# PIC32MZ2048EFM124 register map
Vendor: Microchip
Registers are 32-bit, read-write, reset 0x0 unless marked. A register's access mark holds for its fields unless they carry their own. Addresses are absolute, and some are shared; only a register's first bit layout is shown; [hi:lo] are bit positions; {n}, {i} and the like mark numbered series.

## PORTH
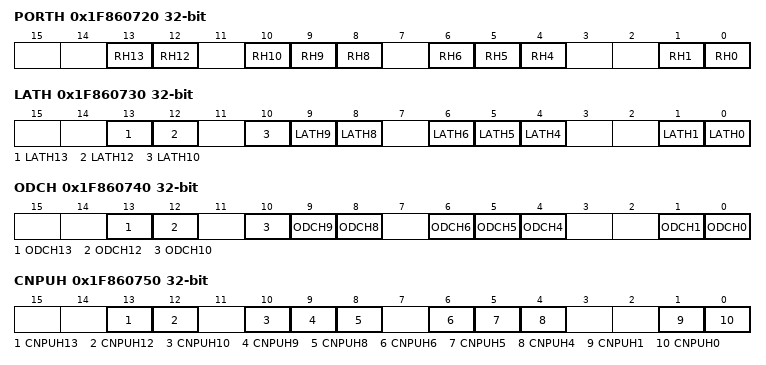
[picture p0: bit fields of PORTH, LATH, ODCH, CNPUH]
0x1F860720 PORTH reset not defined — (power-on value ------------------xx-xxx-xxx--xx)
  [13] RH13, [12] RH12, [10] RH10, [9] RH9, [8] RH8, [6] RH6, [5] RH5, [4] RH4, [1] RH1, [0] RH0
0x1F860730 LATH reset not defined — (power-on value ------------------xx-xxx-xxx--xx)
  [13] LATH13, [12] LATH12, [10] LATH10, [9] LATH9, [8] LATH8, [6] LATH6, [5] LATH5, [4] LATH4, [1] LATH1, [0] LATH0
0x1F860740 ODCH
  [13] ODCH13, [12] ODCH12, [10] ODCH10, [9] ODCH9, [8] ODCH8, [6] ODCH6, [5] ODCH5, [4] ODCH4, [1] ODCH1, [0] ODCH0
0x1F860750 CNPUH
  [13] CNPUH13, [12] CNPUH12, [10] CNPUH10, [9] CNPUH9, [8] CNPUH8, [6] CNPUH6, [5] CNPUH5, [4] CNPUH4, [1] CNPUH1, [0] CNPUH0
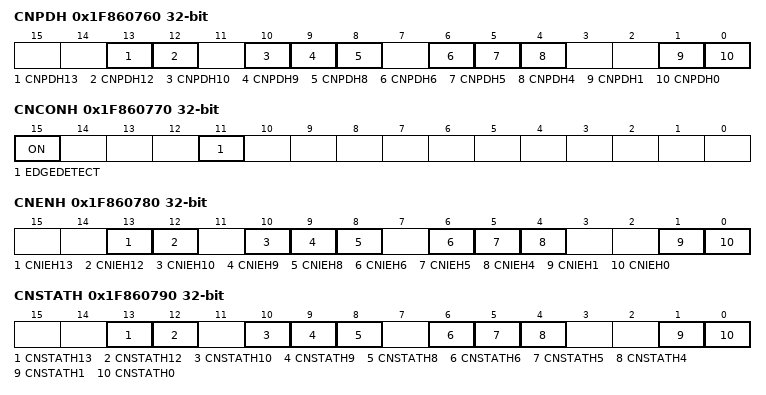
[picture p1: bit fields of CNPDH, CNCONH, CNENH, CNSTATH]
0x1F860760 CNPDH
  [13] CNPDH13, [12] CNPDH12, [10] CNPDH10, [9] CNPDH9, [8] CNPDH8, [6] CNPDH6, [5] CNPDH5, [4] CNPDH4, [1] CNPDH1, [0] CNPDH0
0x1F860770 CNCONH
  [15] ON, [11] EDGEDETECT
0x1F860780 CNENH
  [13] CNIEH13, [12] CNIEH12, [10] CNIEH10, [9] CNIEH9, [8] CNIEH8, [6] CNIEH6, [5] CNIEH5, [4] CNIEH4, [1] CNIEH1, [0] CNIEH0
0x1F860790 CNSTATH
  [13] CNSTATH13, [12] CNSTATH12, [10] CNSTATH10, [9] CNSTATH9, [8] CNSTATH8, [6] CNSTATH6, [5] CNSTATH5, [4] CNSTATH4, [1] CNSTATH1, [0] CNSTATH0
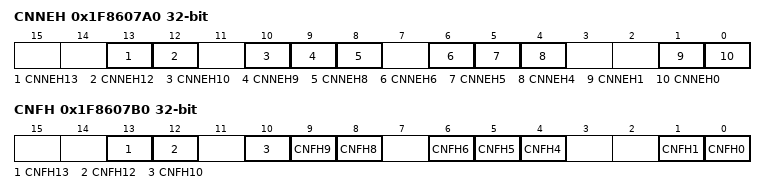
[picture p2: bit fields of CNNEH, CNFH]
0x1F8607A0 CNNEH
  [13] CNNEH13, [12] CNNEH12, [10] CNNEH10, [9] CNNEH9, [8] CNNEH8, [6] CNNEH6, [5] CNNEH5, [4] CNNEH4, [1] CNNEH1, [0] CNNEH0
0x1F8607B0 CNFH
  [13] CNFH13, [12] CNFH12, [10] CNFH10, [9] CNFH9, [8] CNFH8, [6] CNFH6, [5] CNFH5, [4] CNFH4, [1] CNFH1, [0] CNFH0

## PORTJ
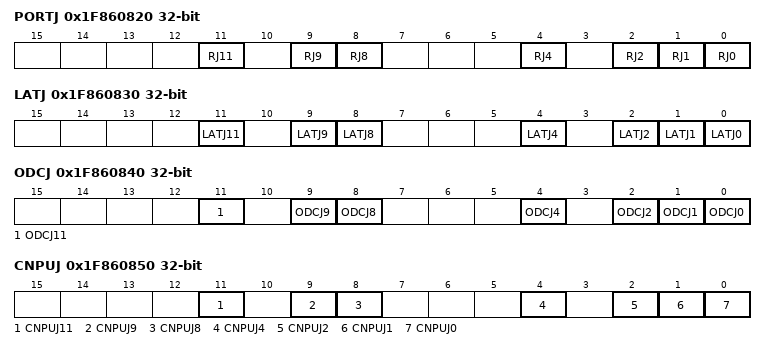
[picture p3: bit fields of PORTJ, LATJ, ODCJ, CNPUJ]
0x1F860820 PORTJ reset not defined — (power-on value --------------------x-xx---x-xxx)
  [11] RJ11, [9] RJ9, [8] RJ8, [4] RJ4, [2] RJ2, [1] RJ1, [0] RJ0
0x1F860830 LATJ reset not defined — (power-on value --------------------x-xx---x-xxx)
  [11] LATJ11, [9] LATJ9, [8] LATJ8, [4] LATJ4, [2] LATJ2, [1] LATJ1, [0] LATJ0
0x1F860840 ODCJ
  [11] ODCJ11, [9] ODCJ9, [8] ODCJ8, [4] ODCJ4, [2] ODCJ2, [1] ODCJ1, [0] ODCJ0
0x1F860850 CNPUJ
  [11] CNPUJ11, [9] CNPUJ9, [8] CNPUJ8, [4] CNPUJ4, [2] CNPUJ2, [1] CNPUJ1, [0] CNPUJ0
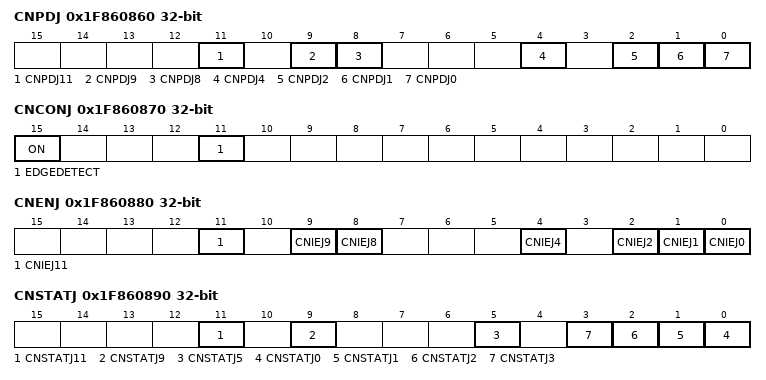
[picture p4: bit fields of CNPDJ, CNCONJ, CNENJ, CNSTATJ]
0x1F860860 CNPDJ
  [11] CNPDJ11, [9] CNPDJ9, [8] CNPDJ8, [4] CNPDJ4, [2] CNPDJ2, [1] CNPDJ1, [0] CNPDJ0
0x1F860870 CNCONJ
  [15] ON, [11] EDGEDETECT
0x1F860880 CNENJ
  [11] CNIEJ11, [9] CNIEJ9, [8] CNIEJ8, [4] CNIEJ4, [2] CNIEJ2, [1] CNIEJ1, [0] CNIEJ0
0x1F860890 CNSTATJ
  [11] CNSTATJ11, [9] CNSTATJ9, [5] CNSTATJ5, [n] CNSTATJ{n} (n=0..3)
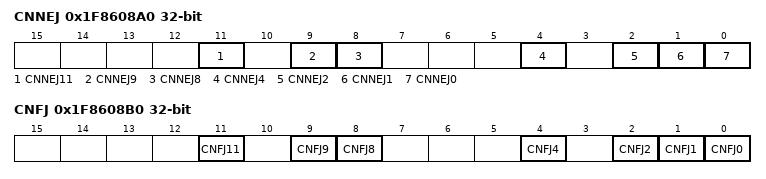
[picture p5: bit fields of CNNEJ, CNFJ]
0x1F8608A0 CNNEJ
  [11] CNNEJ11, [9] CNNEJ9, [8] CNNEJ8, [4] CNNEJ4, [2] CNNEJ2, [1] CNNEJ1, [0] CNNEJ0
0x1F8608B0 CNFJ
  [11] CNFJ11, [9] CNFJ9, [8] CNFJ8, [4] CNFJ4, [2] CNFJ2, [1] CNFJ1, [0] CNFJ0

## CAN1
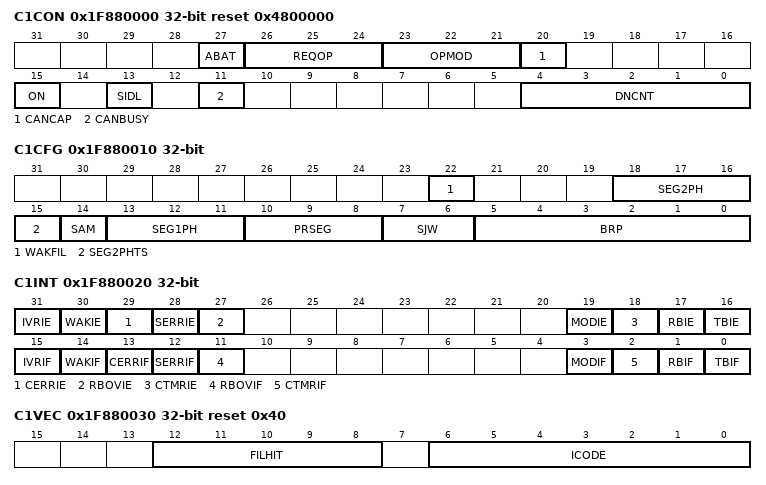
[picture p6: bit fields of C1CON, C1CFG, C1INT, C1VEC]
0x1F880000 C1CON reset 0x4800000
  [27] ABAT — (can only be set)
  [26:24] REQOP
  [23:21] OPMOD ro
  [20] CANCAP
  [15] ON
  [13] SIDL
  [11] CANBUSY ro
  [4:0] DNCNT
0x1F880010 C1CFG
  [22] WAKFIL, [18:16] SEG2PH, [15] SEG2PHTS, [14] SAM, [13:11] SEG1PH, [10:8] PRSEG, [7:6] SJW, [5:0] BRP
0x1F880020 C1INT
  [31] IVRIE, [30] WAKIE, [29] CERRIE, [28] SERRIE, [27] RBOVIE, [19] MODIE, [18] CTMRIE, [17] RBIE, [16] TBIE, [15] IVRIF, [14] WAKIF, [13] CERRIF, [12] SERRIF, [11] RBOVIF, [3] MODIF, [2] CTMRIF, [1] RBIF, [0] TBIF
0x1F880030 C1VEC ro reset 0x40
  [12:8] FILHIT, [6:0] ICODE
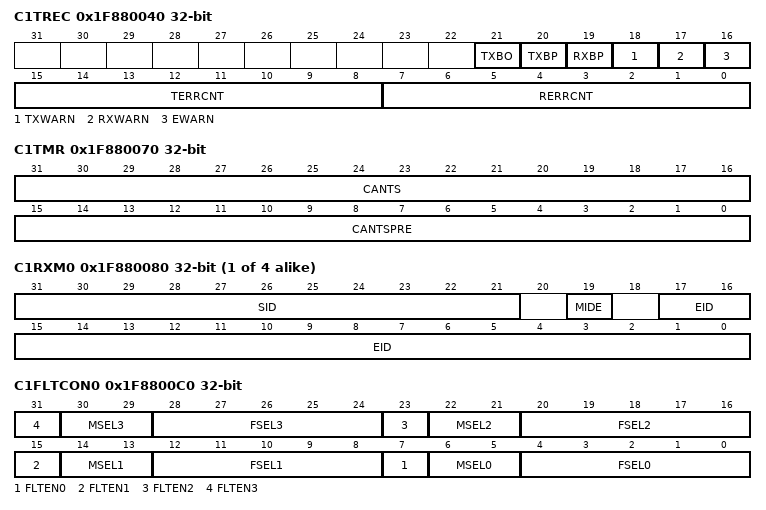
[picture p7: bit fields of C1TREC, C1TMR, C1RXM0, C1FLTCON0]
0x1F880040 C1TREC ro
  [21] TXBO, [20] TXBP, [19] RXBP, [18] TXWARN, [17] RXWARN, [16] EWARN, [15:8] TERRCNT, [7:0] RERRCNT
0x1F880050 C1FSTAT ro
  [31:0] FIFOIP
0x1F880060 C1RXOVF ro
  [31:0] RXOVF
0x1F880070 C1TMR
  [31:16] CANTS, [15:0] CANTSPRE
{0x1F880080+0x10*i} C1RXM{i} (i=0..3)
  [31:21] SID, [19] MIDE, [17:0] EID
0x1F8800C0 C1FLTCON0
  [8n+7] FLTEN{n} (n=0..3), [8n+6:8n+5] MSEL{n} (n=0..3), [8n+4:8n] FSEL{n} (n=0..3)
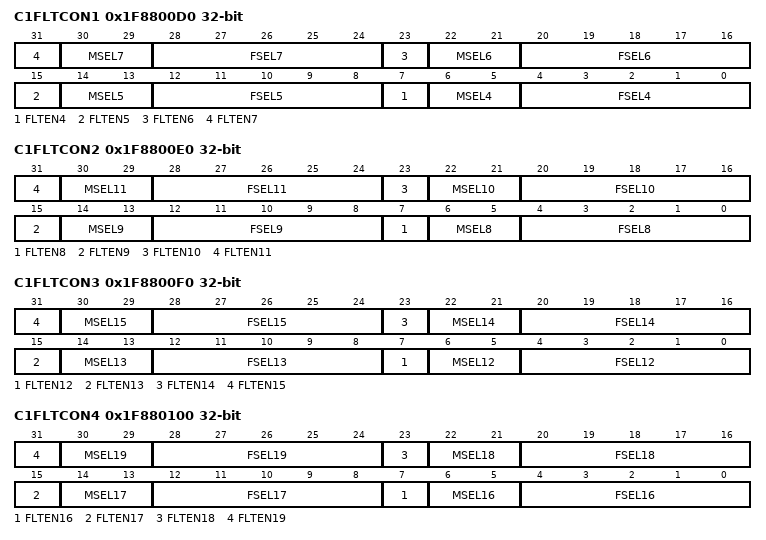
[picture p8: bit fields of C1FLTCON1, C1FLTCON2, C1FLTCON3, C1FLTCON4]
0x1F8800D0 C1FLTCON1
  [8n-25] FLTEN{n} (n=4..7), [8n-26:8n-27] MSEL{n} (n=4..7), [8n-28:8n-32] FSEL{n} (n=4..7)
0x1F8800E0 C1FLTCON2
  [8n-57] FLTEN{n} (n=8..11), [8n-58:8n-59] MSEL{n} (n=8..11), [8n-60:8n-64] FSEL{n} (n=8..11)
0x1F8800F0 C1FLTCON3
  [8n-89] FLTEN{n} (n=12..15), [8n-90:8n-91] MSEL{n} (n=12..15), [8n-92:8n-96] FSEL{n} (n=12..15)
0x1F880100 C1FLTCON4
  [8n-121] FLTEN{n} (n=16..19), [8n-122:8n-123] MSEL{n} (n=16..19), [8n-124:8n-128] FSEL{n} (n=16..19)
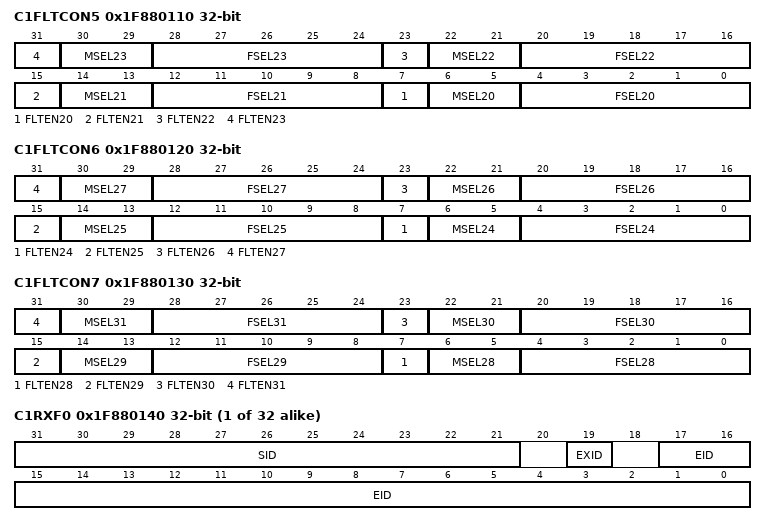
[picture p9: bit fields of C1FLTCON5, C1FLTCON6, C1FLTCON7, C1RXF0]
0x1F880110 C1FLTCON5
  [8n-153] FLTEN{n} (n=20..23), [8n-154:8n-155] MSEL{n} (n=20..23), [8n-156:8n-160] FSEL{n} (n=20..23)
0x1F880120 C1FLTCON6
  [8n-185] FLTEN{n} (n=24..27), [8n-186:8n-187] MSEL{n} (n=24..27), [8n-188:8n-192] FSEL{n} (n=24..27)
0x1F880130 C1FLTCON7
  [8n-217] FLTEN{n} (n=28..31), [8n-218:8n-219] MSEL{n} (n=28..31), [8n-220:8n-224] FSEL{n} (n=28..31)
{0x1F880140+0x10*i} C1RXF{i} reset not defined (i=0..31) — (power-on value xxxxxxxxxxx0x0xxxxxxxxxxxxxxxxxx)
  [31:21] SID, [19] EXID, [17:0] EID
0x1F880340 C1FIFOBA
  [31:2] FIFOBA
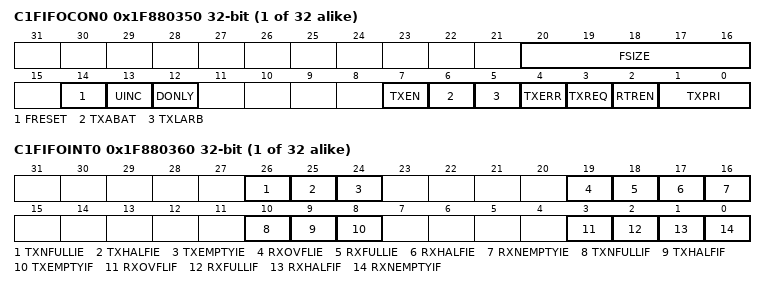
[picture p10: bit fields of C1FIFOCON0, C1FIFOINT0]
{0x1F880350+0x40*i} C1FIFOCON{i} (i=0..31)
  [20:16] FSIZE, [14] FRESET, [13] UINC, [12] DONLY, [7] TXEN, [6] TXABAT, [5] TXLARB, [4] TXERR, [3] TXREQ, [2] RTREN, [1:0] TXPRI
{0x1F880360+0x40*i} C1FIFOINT{i} (i=0..31)
  [26] TXNFULLIE, [25] TXHALFIE, [24] TXEMPTYIE, [19] RXOVFLIE, [18] RXFULLIE, [17] RXHALFIE, [16] RXNEMPTYIE, [10] TXNFULLIF ro, [9] TXHALFIF ro, [8] TXEMPTYIF ro, [3] RXOVFLIF, [2] RXFULLIF ro, [1] RXHALFIF ro, [0] RXNEMPTYIF ro
{0x1F880370+0x40*i} C1FIFOUA{i} ro reset not defined (i=0..31) — (power-on value xxxxxxxxxxxxxxxxxxxxxxxxxxxxxx00)
  [31:2] FIFOUA
{0x1F880380+0x40*i} C1FIFOCI{i} ro (i=0..31)
  [4:0] CFIFOCI
